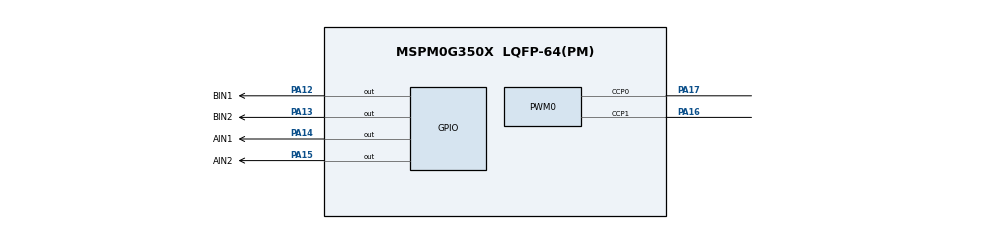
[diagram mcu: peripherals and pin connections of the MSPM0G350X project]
/**
 * @cliArgs --device "MSPM0G350X" --part "Default" --package "LQFP-64(PM)" --product "mspm0_sdk@2.10.00.04"
 * @versions {"tool":"1.26.2+4477"}
 */
const GPIO   = scripting.addModule("/ti/driverlib/GPIO", {}, false);
const PWM    = scripting.addModule("/ti/driverlib/PWM", {}, false);
const TB6612 = GPIO.addInstance();
const PWM0   = PWM.addInstance();
const SYSCTL = scripting.addModule("/ti/driverlib/SYSCTL");

TB6612.$name                          = "TB6612";
TB6612.associatedPins.create(4);
TB6612.associatedPins[0].$name        = "AIN1";
TB6612.associatedPins[0].initialValue = "SET";
TB6612.associatedPins[0].pin.$assign  = "PA14";
TB6612.associatedPins[1].$name        = "AIN2";
TB6612.associatedPins[1].initialValue = "SET";
TB6612.associatedPins[1].pin.$assign  = "PA15";
TB6612.associatedPins[2].$name        = "BIN1";
TB6612.associatedPins[2].initialValue = "SET";
TB6612.associatedPins[2].pin.$assign  = "PA12";
TB6612.associatedPins[3].$name        = "BIN2";
TB6612.associatedPins[3].initialValue = "SET";
TB6612.associatedPins[3].pin.$assign  = "PA13";

PWM0.$name                      = "PWM_0";
PWM0.clockPrescale              = 256;
PWM0.timerCount                 = 1000;
PWM0.pwmMode                    = "EDGE_ALIGN";
PWM0.peripheral.$assign         = "TIMA1";
PWM0.peripheral.ccp0Pin.$assign = "PA17";
PWM0.peripheral.ccp1Pin.$assign = "PA16";
PWM0.PWM_CHANNEL_0.$name        = "C0";
PWM0.PWM_CHANNEL_0.dutyCycle    = 0;
PWM0.PWM_CHANNEL_1.$name        = "C1";
PWM0.PWM_CHANNEL_1.dutyCycle    = 0;

const Board = scripting.addModule("/ti/driverlib/Board", {}, false);

SYSCTL.forceDefaultClkConfig = true;
Board.peripheral.$suggestSolution          = "DEBUGSS";
Board.peripheral.swclkPin.$suggestSolution = "PA20";
Board.peripheral.swdioPin.$suggestSolution = "PA19";
SYSCTL.peripheral.$suggestSolution         = "SYSCTL";
